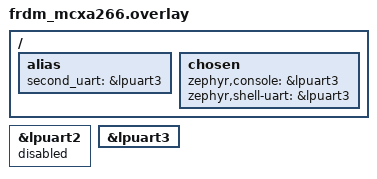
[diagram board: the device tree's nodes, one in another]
/*
 * Copyright 2025 NXP
 *
 * SPDX-License-Identifier: Apache-2.0
 */

/ {
	alias {
		second_uart = &lpuart3;
	};

	chosen {
		zephyr,console = &lpuart3;
		zephyr,shell-uart = &lpuart3;
	};
};

&lpuart2 {
	status = "disabled";
};

&lpuart3 {
	status = "okay";
};
